# ESP32S31_RADIO register map
Vendor: Espressif; Series: ESP32-S31; File version: 3.52
Registers are 32-bit, read-write, no defined reset value unless marked. A register's access mark holds for its fields unless they carry their own. Offsets are from the block's base; [hi:lo] are bit positions; {n}, {i} and the like mark numbered series.

## WIFI_MAC_TXRX_SUFFIX — Eight Wi-Fi-owned direct fresh-read RMW edges after the three external HE callbacks in complete mac_txrx_init. The ninth edge reaches the independently shared physical word at 0x20104C24 and is modeled by SHARED_RADIO_INIT_CONTROL.
Base 0x20104308
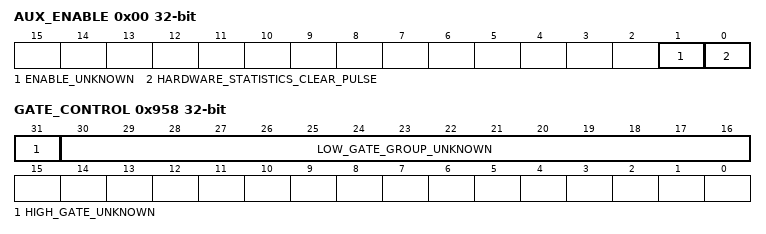
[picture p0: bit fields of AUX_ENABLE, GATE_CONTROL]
0x00 AUX_ENABLE — The TX/RX init suffix sets bit 1. Complete dbg_clr_hw_count reaches esp_test_clr_hw_statistics, which independently pulses bit 0 high then low while the matching core statistics-clear arm is asserted.
  [1] ENABLE_UNKNOWN
  [0] HARDWARE_STATISTICS_CLEAR_PULSE — Set and then cleared by complete esp_test_clr_hw_statistics.
0x918 DEFAULT_IMAGE_A — Complete suffix replaces the low twelve bits with 0x0f0.
  [11:0] LOW_IMAGE_UNKNOWN
0x958 GATE_CONTROL — Complete suffix sets bits 30:16 together, then sets bit 31 through a separate fresh-read edge.
  [31] HIGH_GATE_UNKNOWN, [30:16] LOW_GATE_GROUP_UNKNOWN
0x9A0 FIELD_CONTROL — Complete suffix replaces bits 7:4 with four.
  [7:4] FIELD_UNKNOWN

## SHARED_RADIO_INIT_CONTROL — One physical radio word independently reached by Wi-Fi MAC initialization and Bluetooth receive setup. The owner is protocol-neutral because the two consumers update disjoint fields through fresh-read RMW operations; the name records the observed setup context without assigning an undocumented electrical meaning.
Base 0x20104C24
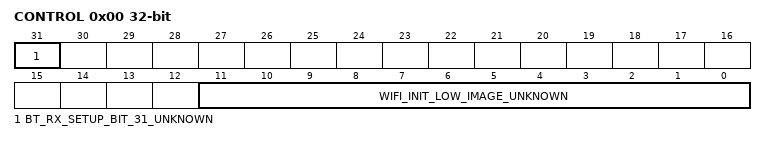
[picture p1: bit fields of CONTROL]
0x00 CONTROL — Complete mac_txrx_init replaces the low twelve bits with 0x0F0. Complete bt_bb_rx_set independently clears bit 31. Bits 30:12 remain unnamed.
  [31] BT_RX_SETUP_BIT_31_UNKNOWN — Complete bt_bb_rx_set clears this bit through a fresh-read RMW while preserving bits 30:0. Its hardware meaning remains unknown.
  [11:0] WIFI_INIT_LOW_IMAGE_UNKNOWN — Complete mac_txrx_init replaces this field with the finite image 0x0F0 while preserving bits 31:12.

## WIFI_MAC_RX_CSI_CONTROL — Multifunction receive/CSI word. Complete mac_last_rxbuf_init sets bit 27; complete hal_init later replaces its low and second bytes through separate RMWs.
Base 0x20104098
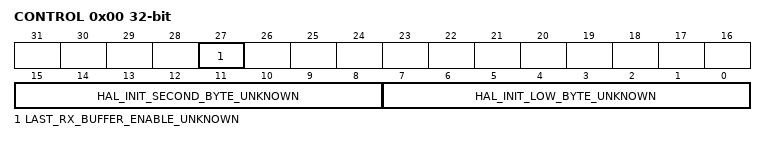
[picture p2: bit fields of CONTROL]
0x00 CONTROL — Complete mac_last_rxbuf_init sets bit 27 after publishing all six table entries and both control groups. Complete hal_init later replaces byte zero with one, then byte one with one through a second fresh-read edge.
  [27] LAST_RX_BUFFER_ENABLE_UNKNOWN — Final set edge of mac_last_rxbuf_init; its narrower interaction with CSI is unknown.
  [15:8] HAL_INIT_SECOND_BYTE_UNKNOWN — Complete hal_init replaces bits 15:8 with one through a separate RMW.
    on write: 1=INITIALIZED
  [7:0] HAL_INIT_LOW_BYTE_UNKNOWN — Complete hal_init replaces bits 7:0 with one.
    on write: 1=INITIALIZED

## WIFI_MAC_LAST_RX_BUFFER — Six three-word last-RX-buffer entries and their shared two-edge enable control, recovered from the complete mac_last_rxbuf_init leaf.
Base 0x20104120
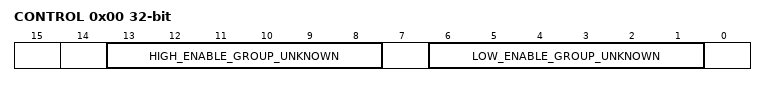
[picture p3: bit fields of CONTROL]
0x00 CONTROL — Complete leaf sets bits 13:8 first, then sets bits 6:1 through a second fresh-read RMW.
  [13:8] HIGH_ENABLE_GROUP_UNKNOWN — All six bits are set by the first control RMW.
  [6:1] LOW_ENABLE_GROUP_UNKNOWN — All six bits are set by the second control RMW.
{0x4+4i} ENTRY_CONTROL{i} (i=0..5) wo — First full-word image for each of six entries.
  [31:0] IMAGE_UNKNOWN
{0x20+4i} ENTRY_PARAMETER_A{i} (i=0..5) wo — Second full-word image for each of six entries.
  [31:0] IMAGE_UNKNOWN
{0x3C+4i} ENTRY_PARAMETER_B{i} (i=0..5) wo — Third full-word image for each of six entries.
  [31:0] IMAGE_UNKNOWN

## WIFI_MAC_CORE_ENABLE — Shared MAC enable gate recovered from the complete hal_enable_mac and hal_disable_mac leaves. The four individual disable-bit meanings are not independently known.
Base 0x20104C00
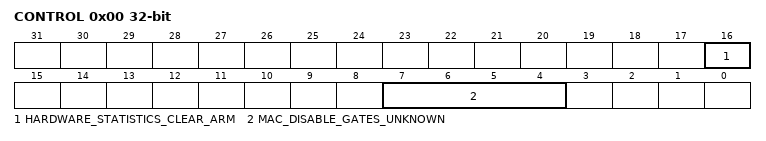
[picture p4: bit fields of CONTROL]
0x00 CONTROL — Complete hal_enable_mac clears bits 7:4 in one fresh-read RMW before publishing its interrupt-mask argument; complete hal_disable_mac sets the same four bits. Complete esp_test_clr_hw_statistics independently asserts bit 16 around the separate 0x20104308 bit-zero clear pulse, then clears bit 16.
  [16] HARDWARE_STATISTICS_CLEAR_ARM — Set before and cleared after the 0x20104308 clear pulse by complete esp_test_clr_hw_statistics.
  [7:4] MAC_DISABLE_GATES_UNKNOWN — Zero is the complete hal_enable_mac image and all ones is the complete hal_disable_mac image; individual gate identities remain unknown.
    on write: 0=ENABLED (Clear all four disable gates.); 15=DISABLED (Set all four disable gates.)
